# cbass_CBASS_QOS_45D20000h register map
Vendor: Texas Instruments
Peripheral module from a debugger description file (folder am62D).
Registers are 32-bit, read-write, reset 0x0 unless marked. A register's access mark holds for its fields unless they carry their own. Offsets are as the file gives them; lines under a group give offsets from that group; [hi:lo] are bit positions; {n}, {i} and the like mark numbered series; 'fields as' and 'values as' point back to an identical list; <NAME> marks a mode.

## cbass_qos
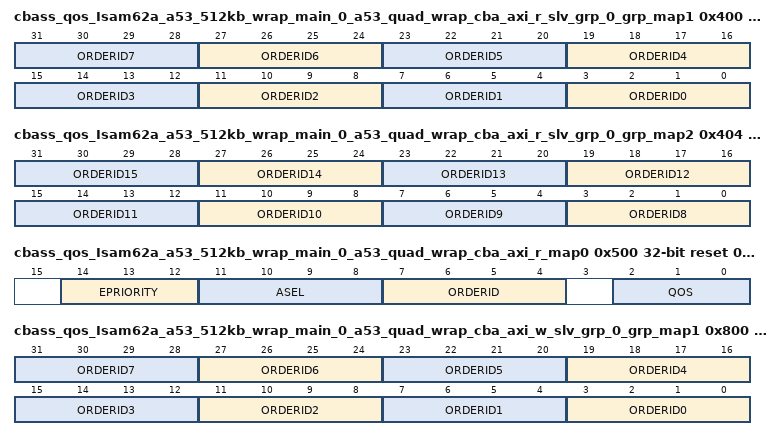
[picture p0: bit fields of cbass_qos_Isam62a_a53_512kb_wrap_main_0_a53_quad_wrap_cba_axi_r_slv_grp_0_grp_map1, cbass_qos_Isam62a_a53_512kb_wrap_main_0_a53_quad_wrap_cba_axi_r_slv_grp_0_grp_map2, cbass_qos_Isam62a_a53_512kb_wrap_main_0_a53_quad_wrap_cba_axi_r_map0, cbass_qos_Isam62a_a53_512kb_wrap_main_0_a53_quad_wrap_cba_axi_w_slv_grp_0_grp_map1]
0x400 cbass_qos_Isam62a_a53_512kb_wrap_main_0_a53_quad_wrap_cba_axi_r_slv_grp_0_grp_map1 — The Group Map Register defines the final orderid for the initiator Isam62a_a53_512kb_wrap_main_0.a53_quad_wrap_cba_axi_r for group slv_grp_0.
  [4n+3:4n] ORDERID{n} (n=0..7) — orderid signal for {n}. Reset Source: domain_default_rst_mod_g_rst_n
0x404 cbass_qos_Isam62a_a53_512kb_wrap_main_0_a53_quad_wrap_cba_axi_r_slv_grp_0_grp_map2 — The Group Map Register defines the final orderid for the initiator Isam62a_a53_512kb_wrap_main_0.a53_quad_wrap_cba_axi_r for group slv_grp_0.
  [4n-29:4n-32] ORDERID{n} (n=8..15) — orderid signal for {n-8}. Reset Source: domain_default_rst_mod_g_rst_n
0x500 cbass_qos_Isam62a_a53_512kb_wrap_main_0_a53_quad_wrap_cba_axi_r_map0 reset 0x7000 — The Map Register defines the fields for the initiator A53SS0 Read Port per channel
  [14:12] EPRIORITY — epriority signal for channel N.This is the strict priority arbitration priority at the destination Reset Source: domain_default_rst_mod_g_rst_n
  [11:8] ASEL — Only used for PCIe, and cache coherency with A53 ACP. So traffic to MSRAM or DDR with asel set to below values will be routed via A53 cache controller. ASEL=0 | normalASEL=1 | PCIe address space for the entire addressASEL=14 | W | cause L2 cache allocation: for cache warming featureASEL=14 | R | does not cause L2 cache allocationASEL=15 | R/W | does not cause L2 cache allocation Reset Source: domain_default_rst_mod_g_rst_n
  [7:4] ORDERID — orderid signal for channel N.Selects to route for load balancing (0-7 uses one route, 8-15 another).Also used by DDR4/LPDDR4 re-ordering to maximize throughput. Order of transactions is only guaranteed with the same orderid Reset Source: domain_default_rst_mod_g_rst_n
  [2:0] QOS — qos signal for channel N. Reset Source: domain_default_rst_mod_g_rst_n
0x800 cbass_qos_Isam62a_a53_512kb_wrap_main_0_a53_quad_wrap_cba_axi_w_slv_grp_0_grp_map1 — The Group Map Register defines the final orderid for the initiator Isam62a_a53_512kb_wrap_main_0.a53_quad_wrap_cba_axi_w for group slv_grp_0.
  fields as cbass_qos_Isam62a_a53_512kb_wrap_main_0_a53_quad_wrap_cba_axi_r_slv_grp_0_grp_map1
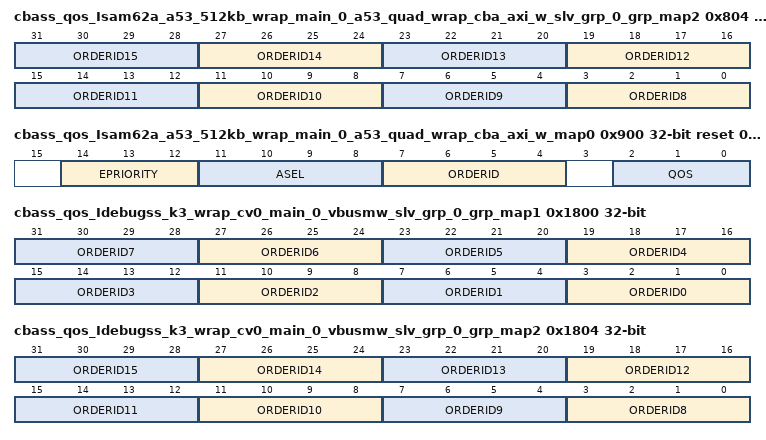
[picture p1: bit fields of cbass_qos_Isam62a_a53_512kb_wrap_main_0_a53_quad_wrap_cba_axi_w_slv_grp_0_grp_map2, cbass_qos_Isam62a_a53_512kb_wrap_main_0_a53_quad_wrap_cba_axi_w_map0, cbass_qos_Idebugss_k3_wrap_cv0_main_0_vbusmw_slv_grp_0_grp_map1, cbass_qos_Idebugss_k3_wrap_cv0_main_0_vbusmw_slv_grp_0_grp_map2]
0x804 cbass_qos_Isam62a_a53_512kb_wrap_main_0_a53_quad_wrap_cba_axi_w_slv_grp_0_grp_map2 — The Group Map Register defines the final orderid for the initiator Isam62a_a53_512kb_wrap_main_0.a53_quad_wrap_cba_axi_w for group slv_grp_0.
  fields as cbass_qos_Isam62a_a53_512kb_wrap_main_0_a53_quad_wrap_cba_axi_r_slv_grp_0_grp_map2
0x900 cbass_qos_Isam62a_a53_512kb_wrap_main_0_a53_quad_wrap_cba_axi_w_map0 reset 0x7000 — The Map Register defines the fields for the initiator A53SS0 Write Port per channel
  fields as cbass_qos_Isam62a_a53_512kb_wrap_main_0_a53_quad_wrap_cba_axi_r_map0
0x1800 cbass_qos_Idebugss_k3_wrap_cv0_main_0_vbusmw_slv_grp_0_grp_map1 — The Group Map Register defines the final orderid for the initiator Idebugss_k3_wrap_cv0_main_0.vbusmw for group slv_grp_0.
  fields as cbass_qos_Isam62a_a53_512kb_wrap_main_0_a53_quad_wrap_cba_axi_r_slv_grp_0_grp_map1
0x1804 cbass_qos_Idebugss_k3_wrap_cv0_main_0_vbusmw_slv_grp_0_grp_map2 — The Group Map Register defines the final orderid for the initiator Idebugss_k3_wrap_cv0_main_0.vbusmw for group slv_grp_0.
  fields as cbass_qos_Isam62a_a53_512kb_wrap_main_0_a53_quad_wrap_cba_axi_r_slv_grp_0_grp_map2
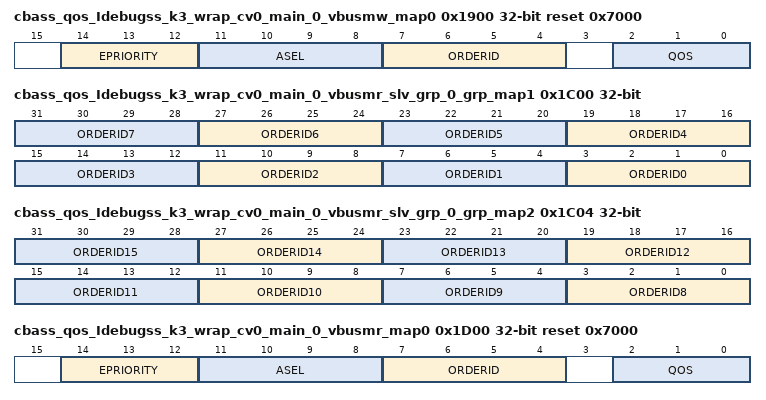
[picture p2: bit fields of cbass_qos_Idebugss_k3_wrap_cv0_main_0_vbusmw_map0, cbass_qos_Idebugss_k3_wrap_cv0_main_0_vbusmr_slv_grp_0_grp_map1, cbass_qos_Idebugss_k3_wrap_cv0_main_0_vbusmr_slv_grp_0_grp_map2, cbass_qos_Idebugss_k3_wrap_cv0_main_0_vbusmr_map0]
0x1900 cbass_qos_Idebugss_k3_wrap_cv0_main_0_vbusmw_map0 reset 0x7000 — The Map Register defines the fields for the initiator DEBUGSS0 Write Port per channel
  fields as cbass_qos_Isam62a_a53_512kb_wrap_main_0_a53_quad_wrap_cba_axi_r_map0
0x1C00 cbass_qos_Idebugss_k3_wrap_cv0_main_0_vbusmr_slv_grp_0_grp_map1 — The Group Map Register defines the final orderid for the initiator Idebugss_k3_wrap_cv0_main_0.vbusmr for group slv_grp_0.
  fields as cbass_qos_Isam62a_a53_512kb_wrap_main_0_a53_quad_wrap_cba_axi_r_slv_grp_0_grp_map1
0x1C04 cbass_qos_Idebugss_k3_wrap_cv0_main_0_vbusmr_slv_grp_0_grp_map2 — The Group Map Register defines the final orderid for the initiator Idebugss_k3_wrap_cv0_main_0.vbusmr for group slv_grp_0.
  fields as cbass_qos_Isam62a_a53_512kb_wrap_main_0_a53_quad_wrap_cba_axi_r_slv_grp_0_grp_map2
0x1D00 cbass_qos_Idebugss_k3_wrap_cv0_main_0_vbusmr_map0 reset 0x7000 — The Map Register defines the fields for the initiator DEBUGSS0 Read Port per channel
  fields as cbass_qos_Isam62a_a53_512kb_wrap_main_0_a53_quad_wrap_cba_axi_r_map0
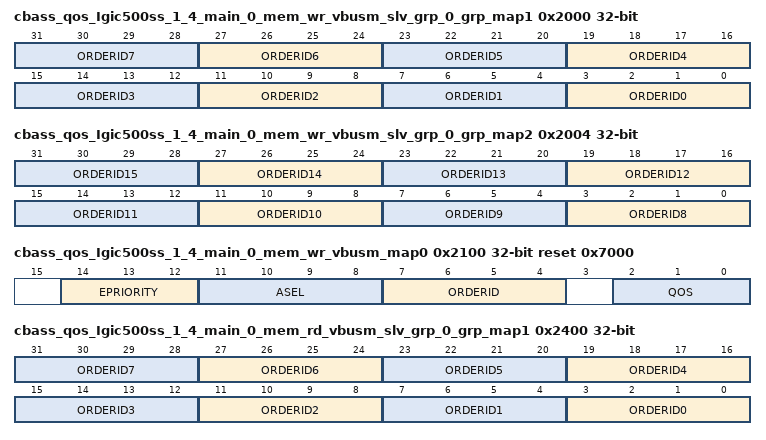
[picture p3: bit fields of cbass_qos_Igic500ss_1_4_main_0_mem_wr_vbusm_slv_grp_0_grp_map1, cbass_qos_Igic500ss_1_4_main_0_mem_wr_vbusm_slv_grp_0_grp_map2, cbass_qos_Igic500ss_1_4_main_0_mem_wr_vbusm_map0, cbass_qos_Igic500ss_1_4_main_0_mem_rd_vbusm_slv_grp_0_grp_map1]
0x2000 cbass_qos_Igic500ss_1_4_main_0_mem_wr_vbusm_slv_grp_0_grp_map1 — The Group Map Register defines the final orderid for the initiator Igic500ss_1_4_main_0.mem_wr_vbusm for group slv_grp_0.
  fields as cbass_qos_Isam62a_a53_512kb_wrap_main_0_a53_quad_wrap_cba_axi_r_slv_grp_0_grp_map1
0x2004 cbass_qos_Igic500ss_1_4_main_0_mem_wr_vbusm_slv_grp_0_grp_map2 — The Group Map Register defines the final orderid for the initiator Igic500ss_1_4_main_0.mem_wr_vbusm for group slv_grp_0.
  fields as cbass_qos_Isam62a_a53_512kb_wrap_main_0_a53_quad_wrap_cba_axi_r_slv_grp_0_grp_map2
0x2100 cbass_qos_Igic500ss_1_4_main_0_mem_wr_vbusm_map0 reset 0x7000 — The Map Register defines the fields for the initiator GICSS0 Write Port per channel
  fields as cbass_qos_Isam62a_a53_512kb_wrap_main_0_a53_quad_wrap_cba_axi_r_map0
0x2400 cbass_qos_Igic500ss_1_4_main_0_mem_rd_vbusm_slv_grp_0_grp_map1 — The Group Map Register defines the final orderid for the initiator Igic500ss_1_4_main_0.mem_rd_vbusm for group slv_grp_0.
  fields as cbass_qos_Isam62a_a53_512kb_wrap_main_0_a53_quad_wrap_cba_axi_r_slv_grp_0_grp_map1
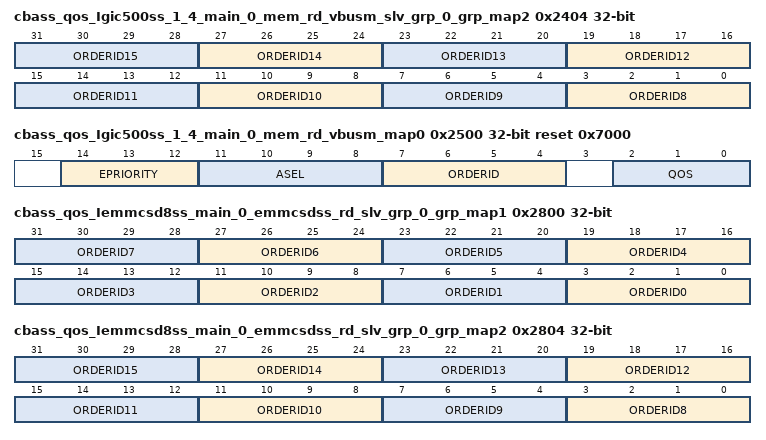
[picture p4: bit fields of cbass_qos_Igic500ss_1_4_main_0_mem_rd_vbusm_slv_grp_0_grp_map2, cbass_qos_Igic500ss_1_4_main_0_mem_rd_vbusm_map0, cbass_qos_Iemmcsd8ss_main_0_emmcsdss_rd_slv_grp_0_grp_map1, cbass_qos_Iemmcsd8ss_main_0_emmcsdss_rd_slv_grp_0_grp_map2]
0x2404 cbass_qos_Igic500ss_1_4_main_0_mem_rd_vbusm_slv_grp_0_grp_map2 — The Group Map Register defines the final orderid for the initiator Igic500ss_1_4_main_0.mem_rd_vbusm for group slv_grp_0.
  fields as cbass_qos_Isam62a_a53_512kb_wrap_main_0_a53_quad_wrap_cba_axi_r_slv_grp_0_grp_map2
0x2500 cbass_qos_Igic500ss_1_4_main_0_mem_rd_vbusm_map0 reset 0x7000 — The Map Register defines the fields for the initiator GICSS0 Read Port per channel
  fields as cbass_qos_Isam62a_a53_512kb_wrap_main_0_a53_quad_wrap_cba_axi_r_map0
0x2800 cbass_qos_Iemmcsd8ss_main_0_emmcsdss_rd_slv_grp_0_grp_map1 — The Group Map Register defines the final orderid for the initiator Iemmcsd8ss_main_0.emmcsdss_rd for group slv_grp_0.
  fields as cbass_qos_Isam62a_a53_512kb_wrap_main_0_a53_quad_wrap_cba_axi_r_slv_grp_0_grp_map1
0x2804 cbass_qos_Iemmcsd8ss_main_0_emmcsdss_rd_slv_grp_0_grp_map2 — The Group Map Register defines the final orderid for the initiator Iemmcsd8ss_main_0.emmcsdss_rd for group slv_grp_0.
  fields as cbass_qos_Isam62a_a53_512kb_wrap_main_0_a53_quad_wrap_cba_axi_r_slv_grp_0_grp_map2
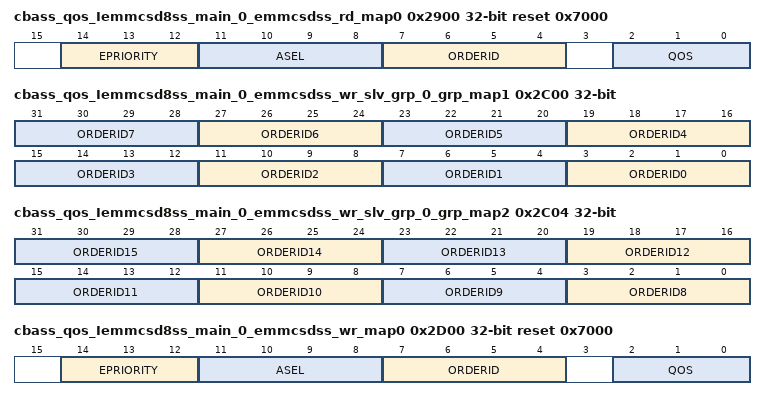
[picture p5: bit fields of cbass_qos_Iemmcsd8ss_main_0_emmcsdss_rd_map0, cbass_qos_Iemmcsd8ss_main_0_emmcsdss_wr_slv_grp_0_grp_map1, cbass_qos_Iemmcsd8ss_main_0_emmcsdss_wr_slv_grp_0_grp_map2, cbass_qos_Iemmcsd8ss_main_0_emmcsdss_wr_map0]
0x2900 cbass_qos_Iemmcsd8ss_main_0_emmcsdss_rd_map0 reset 0x7000 — The Map Register defines the fields for the initiator MMCSD0 Read Port per channel
  fields as cbass_qos_Isam62a_a53_512kb_wrap_main_0_a53_quad_wrap_cba_axi_r_map0
0x2C00 cbass_qos_Iemmcsd8ss_main_0_emmcsdss_wr_slv_grp_0_grp_map1 — The Group Map Register defines the final orderid for the initiator Iemmcsd8ss_main_0.emmcsdss_wr for group slv_grp_0.
  fields as cbass_qos_Isam62a_a53_512kb_wrap_main_0_a53_quad_wrap_cba_axi_r_slv_grp_0_grp_map1
0x2C04 cbass_qos_Iemmcsd8ss_main_0_emmcsdss_wr_slv_grp_0_grp_map2 — The Group Map Register defines the final orderid for the initiator Iemmcsd8ss_main_0.emmcsdss_wr for group slv_grp_0.
  fields as cbass_qos_Isam62a_a53_512kb_wrap_main_0_a53_quad_wrap_cba_axi_r_slv_grp_0_grp_map2
0x2D00 cbass_qos_Iemmcsd8ss_main_0_emmcsdss_wr_map0 reset 0x7000 — The Map Register defines the fields for the initiator MMCSD0 Write Port per channel
  fields as cbass_qos_Isam62a_a53_512kb_wrap_main_0_a53_quad_wrap_cba_axi_r_map0
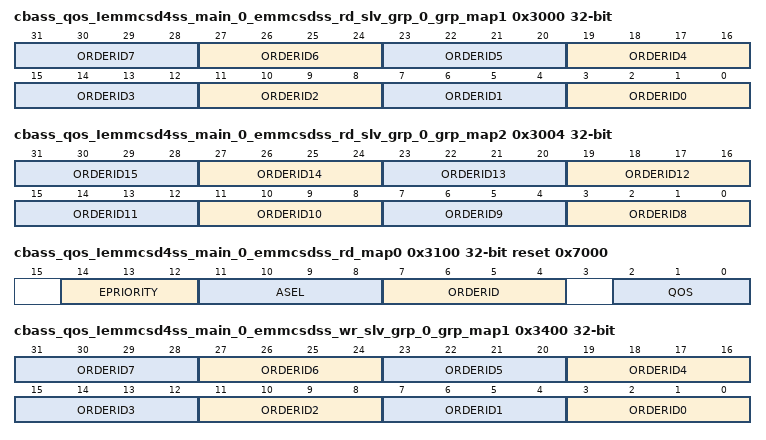
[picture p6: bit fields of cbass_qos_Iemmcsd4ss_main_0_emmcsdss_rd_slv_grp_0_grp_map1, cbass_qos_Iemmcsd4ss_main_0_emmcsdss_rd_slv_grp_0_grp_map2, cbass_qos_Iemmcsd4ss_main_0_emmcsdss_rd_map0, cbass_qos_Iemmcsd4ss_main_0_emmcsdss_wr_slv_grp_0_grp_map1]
0x3000 cbass_qos_Iemmcsd4ss_main_0_emmcsdss_rd_slv_grp_0_grp_map1 — The Group Map Register defines the final orderid for the initiator Iemmcsd4ss_main_0.emmcsdss_rd for group slv_grp_0.
  fields as cbass_qos_Isam62a_a53_512kb_wrap_main_0_a53_quad_wrap_cba_axi_r_slv_grp_0_grp_map1
0x3004 cbass_qos_Iemmcsd4ss_main_0_emmcsdss_rd_slv_grp_0_grp_map2 — The Group Map Register defines the final orderid for the initiator Iemmcsd4ss_main_0.emmcsdss_rd for group slv_grp_0.
  fields as cbass_qos_Isam62a_a53_512kb_wrap_main_0_a53_quad_wrap_cba_axi_r_slv_grp_0_grp_map2
0x3100 cbass_qos_Iemmcsd4ss_main_0_emmcsdss_rd_map0 reset 0x7000 — The Map Register defines the fields for the initiator MMCSD1 Read Port per channel
  fields as cbass_qos_Isam62a_a53_512kb_wrap_main_0_a53_quad_wrap_cba_axi_r_map0
0x3400 cbass_qos_Iemmcsd4ss_main_0_emmcsdss_wr_slv_grp_0_grp_map1 — The Group Map Register defines the final orderid for the initiator Iemmcsd4ss_main_0.emmcsdss_wr for group slv_grp_0.
  fields as cbass_qos_Isam62a_a53_512kb_wrap_main_0_a53_quad_wrap_cba_axi_r_slv_grp_0_grp_map1
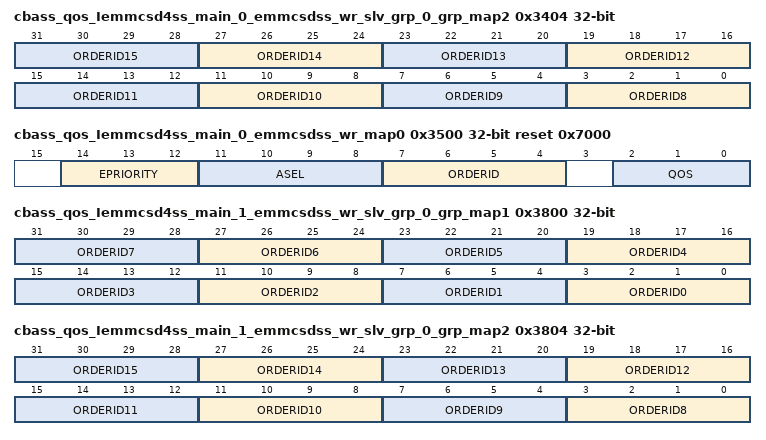
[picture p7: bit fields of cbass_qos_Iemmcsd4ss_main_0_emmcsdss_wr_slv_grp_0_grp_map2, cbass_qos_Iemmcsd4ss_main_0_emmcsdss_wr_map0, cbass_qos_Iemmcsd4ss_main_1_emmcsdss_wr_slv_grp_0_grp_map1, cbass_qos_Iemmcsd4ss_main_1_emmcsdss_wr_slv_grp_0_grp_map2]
0x3404 cbass_qos_Iemmcsd4ss_main_0_emmcsdss_wr_slv_grp_0_grp_map2 — The Group Map Register defines the final orderid for the initiator Iemmcsd4ss_main_0.emmcsdss_wr for group slv_grp_0.
  fields as cbass_qos_Isam62a_a53_512kb_wrap_main_0_a53_quad_wrap_cba_axi_r_slv_grp_0_grp_map2
0x3500 cbass_qos_Iemmcsd4ss_main_0_emmcsdss_wr_map0 reset 0x7000 — The Map Register defines the fields for the initiator MMCSD1 Write Port per channel
  fields as cbass_qos_Isam62a_a53_512kb_wrap_main_0_a53_quad_wrap_cba_axi_r_map0
0x3800 cbass_qos_Iemmcsd4ss_main_1_emmcsdss_wr_slv_grp_0_grp_map1 — The Group Map Register defines the final orderid for the initiator Iemmcsd4ss_main_1.emmcsdss_wr for group slv_grp_0.
  fields as cbass_qos_Isam62a_a53_512kb_wrap_main_0_a53_quad_wrap_cba_axi_r_slv_grp_0_grp_map1
0x3804 cbass_qos_Iemmcsd4ss_main_1_emmcsdss_wr_slv_grp_0_grp_map2 — The Group Map Register defines the final orderid for the initiator Iemmcsd4ss_main_1.emmcsdss_wr for group slv_grp_0.
  fields as cbass_qos_Isam62a_a53_512kb_wrap_main_0_a53_quad_wrap_cba_axi_r_slv_grp_0_grp_map2
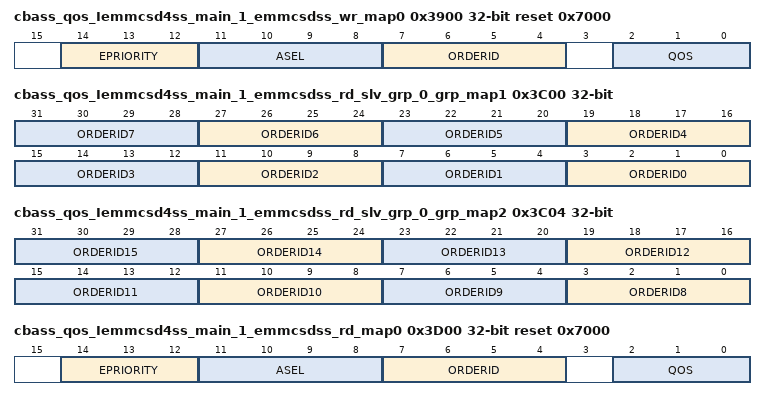
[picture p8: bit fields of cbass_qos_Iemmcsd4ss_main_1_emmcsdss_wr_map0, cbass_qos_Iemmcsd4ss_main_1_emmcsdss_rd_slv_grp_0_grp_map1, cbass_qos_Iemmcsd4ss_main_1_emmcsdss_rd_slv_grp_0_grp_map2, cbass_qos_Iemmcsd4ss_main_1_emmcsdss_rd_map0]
0x3900 cbass_qos_Iemmcsd4ss_main_1_emmcsdss_wr_map0 reset 0x7000 — The Map Register defines the fields for the initiator MMCSD2 Write Port per channel
  fields as cbass_qos_Isam62a_a53_512kb_wrap_main_0_a53_quad_wrap_cba_axi_r_map0
0x3C00 cbass_qos_Iemmcsd4ss_main_1_emmcsdss_rd_slv_grp_0_grp_map1 — The Group Map Register defines the final orderid for the initiator Iemmcsd4ss_main_1.emmcsdss_rd for group slv_grp_0.
  fields as cbass_qos_Isam62a_a53_512kb_wrap_main_0_a53_quad_wrap_cba_axi_r_slv_grp_0_grp_map1
0x3C04 cbass_qos_Iemmcsd4ss_main_1_emmcsdss_rd_slv_grp_0_grp_map2 — The Group Map Register defines the final orderid for the initiator Iemmcsd4ss_main_1.emmcsdss_rd for group slv_grp_0.
  fields as cbass_qos_Isam62a_a53_512kb_wrap_main_0_a53_quad_wrap_cba_axi_r_slv_grp_0_grp_map2
0x3D00 cbass_qos_Iemmcsd4ss_main_1_emmcsdss_rd_map0 reset 0x7000 — The Map Register defines the fields for the initiator MMCSD2 Read Port per channel
  fields as cbass_qos_Isam62a_a53_512kb_wrap_main_0_a53_quad_wrap_cba_axi_r_map0
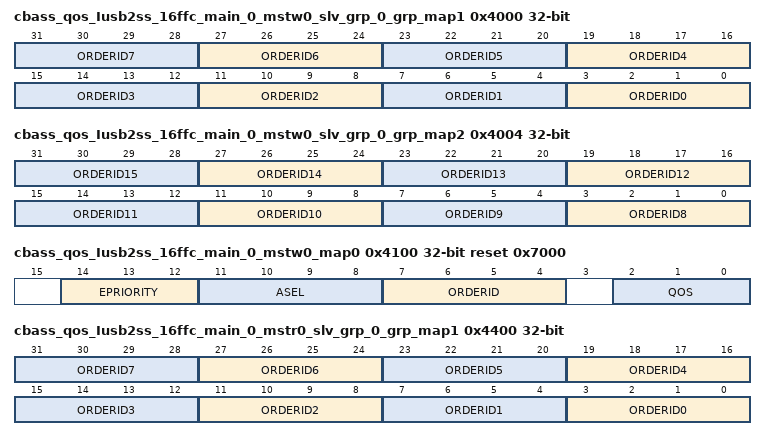
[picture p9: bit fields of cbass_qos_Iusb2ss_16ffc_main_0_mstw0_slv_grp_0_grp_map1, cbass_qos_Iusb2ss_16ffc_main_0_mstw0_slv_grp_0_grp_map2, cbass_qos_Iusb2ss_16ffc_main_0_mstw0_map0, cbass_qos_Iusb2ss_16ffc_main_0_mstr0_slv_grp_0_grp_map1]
0x4000 cbass_qos_Iusb2ss_16ffc_main_0_mstw0_slv_grp_0_grp_map1 — The Group Map Register defines the final orderid for the initiator Iusb2ss_16ffc_main_0.mstw0 for group slv_grp_0.
  fields as cbass_qos_Isam62a_a53_512kb_wrap_main_0_a53_quad_wrap_cba_axi_r_slv_grp_0_grp_map1
0x4004 cbass_qos_Iusb2ss_16ffc_main_0_mstw0_slv_grp_0_grp_map2 — The Group Map Register defines the final orderid for the initiator Iusb2ss_16ffc_main_0.mstw0 for group slv_grp_0.
  fields as cbass_qos_Isam62a_a53_512kb_wrap_main_0_a53_quad_wrap_cba_axi_r_slv_grp_0_grp_map2
0x4100 cbass_qos_Iusb2ss_16ffc_main_0_mstw0_map0 reset 0x7000 — The Map Register defines the fields for the initiator USB0 Write Port per channel
  fields as cbass_qos_Isam62a_a53_512kb_wrap_main_0_a53_quad_wrap_cba_axi_r_map0
0x4400 cbass_qos_Iusb2ss_16ffc_main_0_mstr0_slv_grp_0_grp_map1 — The Group Map Register defines the final orderid for the initiator Iusb2ss_16ffc_main_0.mstr0 for group slv_grp_0.
  fields as cbass_qos_Isam62a_a53_512kb_wrap_main_0_a53_quad_wrap_cba_axi_r_slv_grp_0_grp_map1
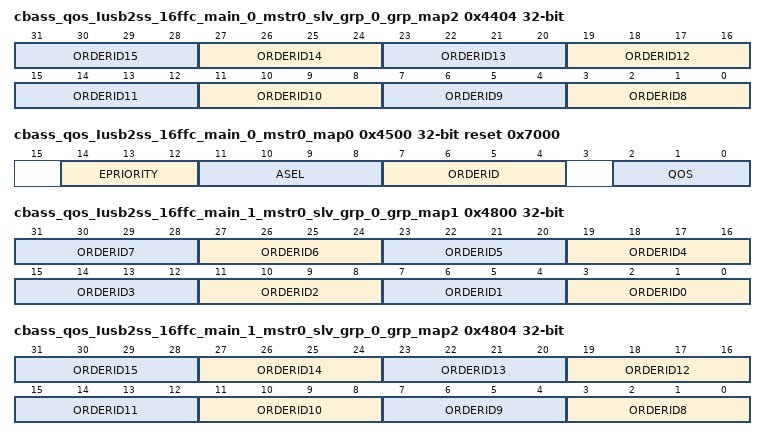
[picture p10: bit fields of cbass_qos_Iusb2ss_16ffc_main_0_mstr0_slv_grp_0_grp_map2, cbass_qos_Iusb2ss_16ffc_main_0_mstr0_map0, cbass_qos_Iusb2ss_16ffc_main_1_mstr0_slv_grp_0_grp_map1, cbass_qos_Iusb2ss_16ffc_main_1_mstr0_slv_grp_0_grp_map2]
0x4404 cbass_qos_Iusb2ss_16ffc_main_0_mstr0_slv_grp_0_grp_map2 — The Group Map Register defines the final orderid for the initiator Iusb2ss_16ffc_main_0.mstr0 for group slv_grp_0.
  fields as cbass_qos_Isam62a_a53_512kb_wrap_main_0_a53_quad_wrap_cba_axi_r_slv_grp_0_grp_map2
0x4500 cbass_qos_Iusb2ss_16ffc_main_0_mstr0_map0 reset 0x7000 — The Map Register defines the fields for the initiator USB0 Read Port per channel
  fields as cbass_qos_Isam62a_a53_512kb_wrap_main_0_a53_quad_wrap_cba_axi_r_map0
0x4800 cbass_qos_Iusb2ss_16ffc_main_1_mstr0_slv_grp_0_grp_map1 — The Group Map Register defines the final orderid for the initiator Iusb2ss_16ffc_main_1.mstr0 for group slv_grp_0.
  fields as cbass_qos_Isam62a_a53_512kb_wrap_main_0_a53_quad_wrap_cba_axi_r_slv_grp_0_grp_map1
0x4804 cbass_qos_Iusb2ss_16ffc_main_1_mstr0_slv_grp_0_grp_map2 — The Group Map Register defines the final orderid for the initiator Iusb2ss_16ffc_main_1.mstr0 for group slv_grp_0.
  fields as cbass_qos_Isam62a_a53_512kb_wrap_main_0_a53_quad_wrap_cba_axi_r_slv_grp_0_grp_map2
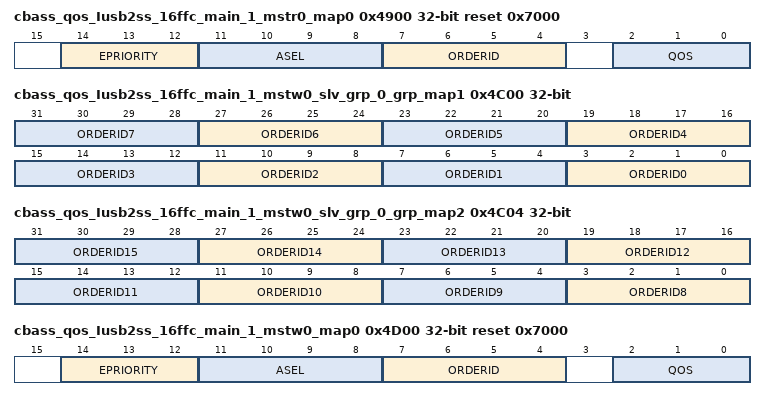
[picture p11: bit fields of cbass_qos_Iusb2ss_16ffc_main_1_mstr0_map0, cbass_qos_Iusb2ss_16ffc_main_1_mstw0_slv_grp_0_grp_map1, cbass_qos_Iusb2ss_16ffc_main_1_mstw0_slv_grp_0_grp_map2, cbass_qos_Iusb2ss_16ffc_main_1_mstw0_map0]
0x4900 cbass_qos_Iusb2ss_16ffc_main_1_mstr0_map0 reset 0x7000 — The Map Register defines the fields for the initiator USB1 Read Port per channel
  fields as cbass_qos_Isam62a_a53_512kb_wrap_main_0_a53_quad_wrap_cba_axi_r_map0
0x4C00 cbass_qos_Iusb2ss_16ffc_main_1_mstw0_slv_grp_0_grp_map1 — The Group Map Register defines the final orderid for the initiator Iusb2ss_16ffc_main_1.mstw0 for group slv_grp_0.
  fields as cbass_qos_Isam62a_a53_512kb_wrap_main_0_a53_quad_wrap_cba_axi_r_slv_grp_0_grp_map1
0x4C04 cbass_qos_Iusb2ss_16ffc_main_1_mstw0_slv_grp_0_grp_map2 — The Group Map Register defines the final orderid for the initiator Iusb2ss_16ffc_main_1.mstw0 for group slv_grp_0.
  fields as cbass_qos_Isam62a_a53_512kb_wrap_main_0_a53_quad_wrap_cba_axi_r_slv_grp_0_grp_map2
0x4D00 cbass_qos_Iusb2ss_16ffc_main_1_mstw0_map0 reset 0x7000 — The Map Register defines the fields for the initiator USB1 Write Port per channel
  fields as cbass_qos_Isam62a_a53_512kb_wrap_main_0_a53_quad_wrap_cba_axi_r_map0
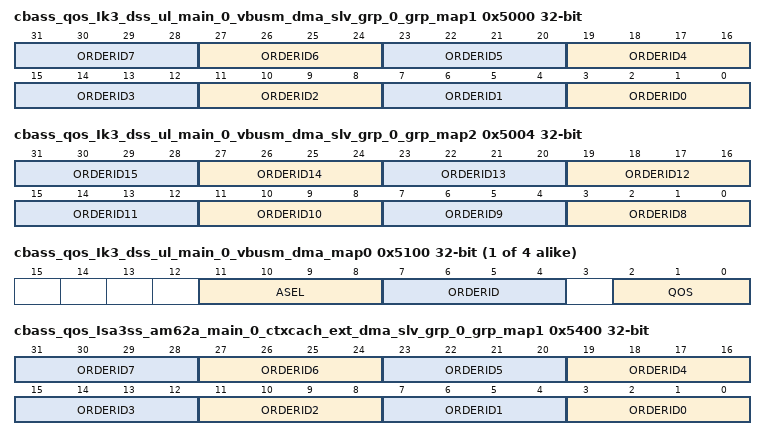
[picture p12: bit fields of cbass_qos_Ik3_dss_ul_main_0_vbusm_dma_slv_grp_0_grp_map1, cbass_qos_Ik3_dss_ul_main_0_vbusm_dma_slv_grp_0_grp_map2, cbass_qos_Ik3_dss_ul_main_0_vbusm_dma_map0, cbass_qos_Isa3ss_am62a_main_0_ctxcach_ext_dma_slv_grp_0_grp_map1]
0x5000 cbass_qos_Ik3_dss_ul_main_0_vbusm_dma_slv_grp_0_grp_map1 — The Group Map Register defines the final orderid for the initiator Ik3_dss_ul_main_0.vbusm_dma for group slv_grp_0.
  fields as cbass_qos_Isam62a_a53_512kb_wrap_main_0_a53_quad_wrap_cba_axi_r_slv_grp_0_grp_map1
0x5004 cbass_qos_Ik3_dss_ul_main_0_vbusm_dma_slv_grp_0_grp_map2 — The Group Map Register defines the final orderid for the initiator Ik3_dss_ul_main_0.vbusm_dma for group slv_grp_0.
  fields as cbass_qos_Isam62a_a53_512kb_wrap_main_0_a53_quad_wrap_cba_axi_r_slv_grp_0_grp_map2
{0x5100+4i} cbass_qos_Ik3_dss_ul_main_0_vbusm_dma_map{i} (i=0..3) — The Map Register defines the fields for the initiator DSS0 Port per channel
  [11:8] ASEL — Only used for PCIe, and cache coherency with A53 ACP. So traffic to MSRAM or DDR with asel set to below values will be routed via A53 cache controller. ASEL=0 | normalASEL=1 | PCIe address space for the entire addressASEL=14 | W | cause L2 cache allocation: for cache warming featureASEL=14 | R | does not cause L2 cache allocationASEL=15 | R/W | does not cause L2 cache allocation Reset Source: domain_default_rst_mod_g_rst_n
  [7:4] ORDERID — orderid signal for channel N.Selects to route for load balancing (0-7 uses one route, 8-15 another).Also used by DDR4/LPDDR4 re-ordering to maximize throughput. Order of transactions is only guaranteed with the same orderid Reset Source: domain_default_rst_mod_g_rst_n
  [2:0] QOS — qos signal for channel N. Reset Source: domain_default_rst_mod_g_rst_n
0x5400 cbass_qos_Isa3ss_am62a_main_0_ctxcach_ext_dma_slv_grp_0_grp_map1 — The Group Map Register defines the final orderid for the initiator Isa3ss_am62a_main_0.ctxcach_ext_dma for group slv_grp_0.
  fields as cbass_qos_Isam62a_a53_512kb_wrap_main_0_a53_quad_wrap_cba_axi_r_slv_grp_0_grp_map1
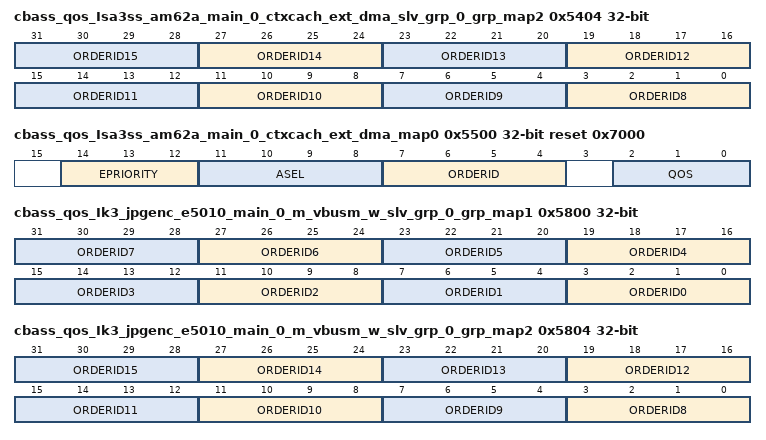
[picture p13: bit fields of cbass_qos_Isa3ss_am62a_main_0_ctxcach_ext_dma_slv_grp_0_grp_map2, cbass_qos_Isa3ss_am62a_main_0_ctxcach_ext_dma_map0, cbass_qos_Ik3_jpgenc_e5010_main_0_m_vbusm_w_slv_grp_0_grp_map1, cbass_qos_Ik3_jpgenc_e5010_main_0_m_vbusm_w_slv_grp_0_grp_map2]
0x5404 cbass_qos_Isa3ss_am62a_main_0_ctxcach_ext_dma_slv_grp_0_grp_map2 — The Group Map Register defines the final orderid for the initiator Isa3ss_am62a_main_0.ctxcach_ext_dma for group slv_grp_0.
  fields as cbass_qos_Isam62a_a53_512kb_wrap_main_0_a53_quad_wrap_cba_axi_r_slv_grp_0_grp_map2
0x5500 cbass_qos_Isa3ss_am62a_main_0_ctxcach_ext_dma_map0 reset 0x7000 — The Map Register defines the fields for the initiator Isa3ss_am62a_main_0.ctxcach_ext_dma per channel.
  fields as cbass_qos_Isam62a_a53_512kb_wrap_main_0_a53_quad_wrap_cba_axi_r_map0
0x5800 cbass_qos_Ik3_jpgenc_e5010_main_0_m_vbusm_w_slv_grp_0_grp_map1 — The Group Map Register defines the final orderid for the initiator Ik3_jpgenc_e5010_main_0.m_vbusm_w for group slv_grp_0.
  fields as cbass_qos_Isam62a_a53_512kb_wrap_main_0_a53_quad_wrap_cba_axi_r_slv_grp_0_grp_map1
0x5804 cbass_qos_Ik3_jpgenc_e5010_main_0_m_vbusm_w_slv_grp_0_grp_map2 — The Group Map Register defines the final orderid for the initiator Ik3_jpgenc_e5010_main_0.m_vbusm_w for group slv_grp_0.
  fields as cbass_qos_Isam62a_a53_512kb_wrap_main_0_a53_quad_wrap_cba_axi_r_slv_grp_0_grp_map2
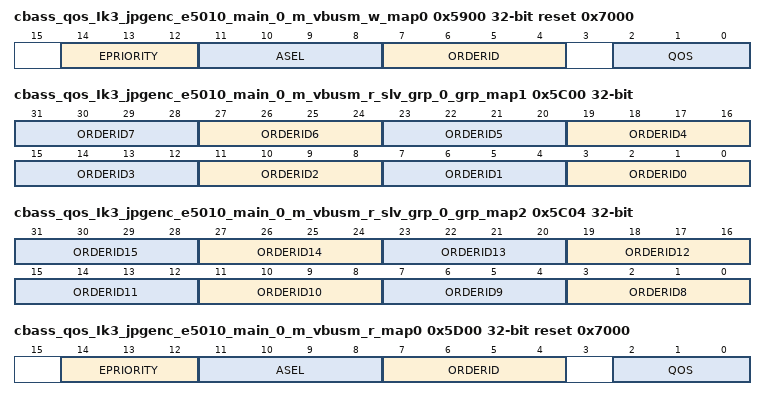
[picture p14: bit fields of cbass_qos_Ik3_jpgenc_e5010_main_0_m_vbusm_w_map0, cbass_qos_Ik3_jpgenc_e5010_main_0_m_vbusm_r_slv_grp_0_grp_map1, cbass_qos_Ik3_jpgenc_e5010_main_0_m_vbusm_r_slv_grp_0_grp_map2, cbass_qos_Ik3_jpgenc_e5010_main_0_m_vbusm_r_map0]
0x5900 cbass_qos_Ik3_jpgenc_e5010_main_0_m_vbusm_w_map0 reset 0x7000 — The Map Register defines the fields for the initiator Ik3_jpgenc_e5010_main_0.m_vbusm_w per channel.
  fields as cbass_qos_Isam62a_a53_512kb_wrap_main_0_a53_quad_wrap_cba_axi_r_map0
0x5C00 cbass_qos_Ik3_jpgenc_e5010_main_0_m_vbusm_r_slv_grp_0_grp_map1 — The Group Map Register defines the final orderid for the initiator Ik3_jpgenc_e5010_main_0.m_vbusm_r for group slv_grp_0.
  fields as cbass_qos_Isam62a_a53_512kb_wrap_main_0_a53_quad_wrap_cba_axi_r_slv_grp_0_grp_map1
0x5C04 cbass_qos_Ik3_jpgenc_e5010_main_0_m_vbusm_r_slv_grp_0_grp_map2 — The Group Map Register defines the final orderid for the initiator Ik3_jpgenc_e5010_main_0.m_vbusm_r for group slv_grp_0.
  fields as cbass_qos_Isam62a_a53_512kb_wrap_main_0_a53_quad_wrap_cba_axi_r_slv_grp_0_grp_map2
0x5D00 cbass_qos_Ik3_jpgenc_e5010_main_0_m_vbusm_r_map0 reset 0x7000 — The Map Register defines the fields for the initiator Ik3_jpgenc_e5010_main_0.m_vbusm_r per channel.
  fields as cbass_qos_Isam62a_a53_512kb_wrap_main_0_a53_quad_wrap_cba_axi_r_map0
0x5D04 cbass_qos_Ik3_jpgenc_e5010_main_0_m_vbusm_r_map1 reset 0x7000 — The Map Register defines the fields for the initiator Ik3_jpgenc_e5010_main_0.m_vbusm_r per channel.
  fields as cbass_qos_Isam62a_a53_512kb_wrap_main_0_a53_quad_wrap_cba_axi_r_map0
0x6800 cbass_qos_Ik3_vpu_wave521cl_main_0_pri_m_vbusm_r_async_slv_grp_0_grp_map1 — The Group Map Register defines the final orderid for the initiator Ik3_vpu_wave521cl_main_0.pri_m_vbusm_r_async for group slv_grp_0.
  fields as cbass_qos_Isam62a_a53_512kb_wrap_main_0_a53_quad_wrap_cba_axi_r_slv_grp_0_grp_map1
0x6804 cbass_qos_Ik3_vpu_wave521cl_main_0_pri_m_vbusm_r_async_slv_grp_0_grp_map2 — The Group Map Register defines the final orderid for the initiator Ik3_vpu_wave521cl_main_0.pri_m_vbusm_r_async for group slv_grp_0.
  fields as cbass_qos_Isam62a_a53_512kb_wrap_main_0_a53_quad_wrap_cba_axi_r_slv_grp_0_grp_map2
{0x6900+4i} cbass_qos_Ik3_vpu_wave521cl_main_0_pri_m_vbusm_r_async_map{i} reset 0x7000 (i=0..4) — The Map Register defines the fields for the initiator CODEC0 Read Port per channel
  fields as cbass_qos_Isam62a_a53_512kb_wrap_main_0_a53_quad_wrap_cba_axi_r_map0
0x6C00 cbass_qos_Ik3_vpu_wave521cl_main_0_pri_m_vbusm_w_async_slv_grp_0_grp_map1 — The Group Map Register defines the final orderid for the initiator Ik3_vpu_wave521cl_main_0.pri_m_vbusm_w_async for group slv_grp_0.
  fields as cbass_qos_Isam62a_a53_512kb_wrap_main_0_a53_quad_wrap_cba_axi_r_slv_grp_0_grp_map1
0x6C04 cbass_qos_Ik3_vpu_wave521cl_main_0_pri_m_vbusm_w_async_slv_grp_0_grp_map2 — The Group Map Register defines the final orderid for the initiator Ik3_vpu_wave521cl_main_0.pri_m_vbusm_w_async for group slv_grp_0.
  fields as cbass_qos_Isam62a_a53_512kb_wrap_main_0_a53_quad_wrap_cba_axi_r_slv_grp_0_grp_map2
{0x6D00+4i} cbass_qos_Ik3_vpu_wave521cl_main_0_pri_m_vbusm_w_async_map{i} reset 0x7000 (i=0..4) — The Map Register defines the fields for the initiator CODEC0 Write Port per channel
  fields as cbass_qos_Isam62a_a53_512kb_wrap_main_0_a53_quad_wrap_cba_axi_r_map0
0x7000 cbass_qos_Ik3_vpu_wave521cl_main_0_sec_m_vbusm_r_async_slv_grp_0_grp_map1 — The Group Map Register defines the final orderid for the initiator Ik3_vpu_wave521cl_main_0.sec_m_vbusm_r_async for group slv_grp_0.
  fields as cbass_qos_Isam62a_a53_512kb_wrap_main_0_a53_quad_wrap_cba_axi_r_slv_grp_0_grp_map1
0x7004 cbass_qos_Ik3_vpu_wave521cl_main_0_sec_m_vbusm_r_async_slv_grp_0_grp_map2 — The Group Map Register defines the final orderid for the initiator Ik3_vpu_wave521cl_main_0.sec_m_vbusm_r_async for group slv_grp_0.
  fields as cbass_qos_Isam62a_a53_512kb_wrap_main_0_a53_quad_wrap_cba_axi_r_slv_grp_0_grp_map2
0x7100 cbass_qos_Ik3_vpu_wave521cl_main_0_sec_m_vbusm_r_async_map0 reset 0x7000 — The Map Register defines the fields for the initiator CODEC0 Read Port per channel
  fields as cbass_qos_Isam62a_a53_512kb_wrap_main_0_a53_quad_wrap_cba_axi_r_map0
0x7400 cbass_qos_Ik3_vpu_wave521cl_main_0_sec_m_vbusm_w_async_slv_grp_0_grp_map1 — The Group Map Register defines the final orderid for the initiator Ik3_vpu_wave521cl_main_0.sec_m_vbusm_w_async for group slv_grp_0.
  fields as cbass_qos_Isam62a_a53_512kb_wrap_main_0_a53_quad_wrap_cba_axi_r_slv_grp_0_grp_map1
0x7404 cbass_qos_Ik3_vpu_wave521cl_main_0_sec_m_vbusm_w_async_slv_grp_0_grp_map2 — The Group Map Register defines the final orderid for the initiator Ik3_vpu_wave521cl_main_0.sec_m_vbusm_w_async for group slv_grp_0.
  fields as cbass_qos_Isam62a_a53_512kb_wrap_main_0_a53_quad_wrap_cba_axi_r_slv_grp_0_grp_map2
0x7500 cbass_qos_Ik3_vpu_wave521cl_main_0_sec_m_vbusm_w_async_map0 reset 0x7000 — The Map Register defines the fields for the initiator CODEC0 Write Port per channel
  fields as cbass_qos_Isam62a_a53_512kb_wrap_main_0_a53_quad_wrap_cba_axi_r_map0
0x7800 cbass_qos_Isam62a_c7xv_wrap_main_0_c7xv_soc_slv_grp_0_grp_map1 — The Group Map Register defines the final orderid for the initiator Isam62a_c7xv_wrap_main_0.c7xv_soc for group slv_grp_0.
  fields as cbass_qos_Isam62a_a53_512kb_wrap_main_0_a53_quad_wrap_cba_axi_r_slv_grp_0_grp_map1
0x7804 cbass_qos_Isam62a_c7xv_wrap_main_0_c7xv_soc_slv_grp_0_grp_map2 — The Group Map Register defines the final orderid for the initiator Isam62a_c7xv_wrap_main_0.c7xv_soc for group slv_grp_0.
  fields as cbass_qos_Isam62a_a53_512kb_wrap_main_0_a53_quad_wrap_cba_axi_r_slv_grp_0_grp_map2
0x7900 cbass_qos_Isam62a_c7xv_wrap_main_0_c7xv_soc_map0 — The Map Register defines the fields for the initiator Isam62a_c7xv_wrap_main_0.c7xv_soc per channel.
  [7:4] ORDERID — orderid signal for channel N.Selects to route for load balancing (0-7 uses one route, 8-15 another).Also used by DDR4/LPDDR4 re-ordering to maximize throughput. Order of transactions is only guaranteed with the same orderid Reset Source: domain_default_rst_mod_g_rst_n
  [2:0] QOS — qos signal for channel N. Reset Source: domain_default_rst_mod_g_rst_n
0x7904 cbass_qos_Isam62a_c7xv_wrap_main_0_c7xv_soc_map1 — The Map Register defines the fields for the initiator Isam62a_c7xv_wrap_main_0.c7xv_soc per channel.
  fields as cbass_qos_Isam62a_c7xv_wrap_main_0_c7xv_soc_map0
0x8000 cbass_qos_Isam62a_vpac_wrap_main_0_ldc0_m_mst_slv_grp_0_grp_map1 — The Group Map Register defines the final orderid for the initiator Isam62a_vpac_wrap_main_0.ldc0_m_mst for group slv_grp_0.
  fields as cbass_qos_Isam62a_a53_512kb_wrap_main_0_a53_quad_wrap_cba_axi_r_slv_grp_0_grp_map1
0x8004 cbass_qos_Isam62a_vpac_wrap_main_0_ldc0_m_mst_slv_grp_0_grp_map2 — The Group Map Register defines the final orderid for the initiator Isam62a_vpac_wrap_main_0.ldc0_m_mst for group slv_grp_0.
  fields as cbass_qos_Isam62a_a53_512kb_wrap_main_0_a53_quad_wrap_cba_axi_r_slv_grp_0_grp_map2
{0x8100+4i} cbass_qos_Isam62a_vpac_wrap_main_0_ldc0_m_mst_map{i} reset 0x7000 (i=0..2) — The Map Register defines the fields for the initiator Isam62a_vpac_wrap_main_0.ldc0_m_mst per channel.
  fields as cbass_qos_Isam62a_a53_512kb_wrap_main_0_a53_quad_wrap_cba_axi_r_map0
